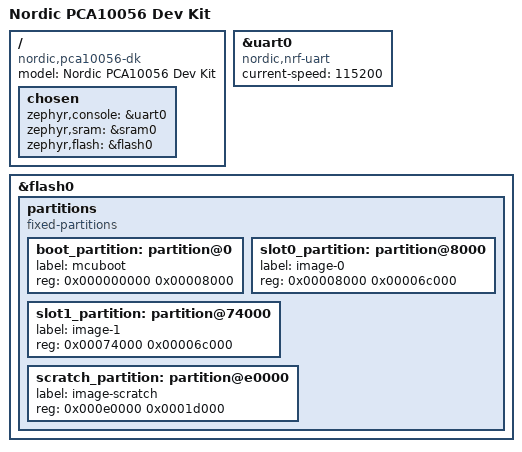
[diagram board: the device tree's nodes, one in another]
/*
 * Copyright (c) 2017 Linaro Limited
 *
 * SPDX-License-Identifier: Apache-2.0
 */

/dts-v1/;
#include <nordic/nrf52840.dtsi>

/ {
	model = "Nordic PCA10056 Dev Kit";
	compatible = "nordic,pca10056-dk", "nordic,nrf52840-qiaa",
		     "nordic,nrf52840";

	chosen {
		zephyr,console = &uart0;
		zephyr,sram = &sram0;
		zephyr,flash = &flash0;
	};
};

&uart0 {
	compatible = "nordic,nrf-uart";
	current-speed = <115200>;
	status = "ok";
};

&flash0 {
	/*
	 * If chosen's zephyr,code-partition
	 * is unset, the image will be linked
	 * into the entire flash device.  If
	 * it points to an individual
	 * partition, the code will be linked
	 * to, and restricted to that
	 * partition.
	 */
	partitions {
		compatible = "fixed-partitions";
		#address-cells = <1>;
		#size-cells = <1>;

		boot_partition: partition@0 {
			label = "mcuboot";
			reg = <0x000000000 0x00008000>;
		};
		slot0_partition: partition@8000 {
			label = "image-0";
			reg = <0x00008000 0x00006c000>;
		};
		slot1_partition: partition@74000 {
			label = "image-1";
			reg = <0x00074000 0x00006c000>;
		};
		scratch_partition: partition@e0000 {
			label = "image-scratch";
			reg = <0x000e0000 0x0001d000>;
		};

		/*
		 * The flash starting at 0x000fd000 and ending at 0x000fffff
		 * (sectors 253 through 255) is reserved for use by the
		 * application.
		 */
	};
};
